# ENCODER0_REG_TOPAZ_VLC_CORE_0 register map
Vendor: Texas Instruments
Peripheral module from a debugger description file (folder J7ES).
Registers are 32-bit, read-only, reset values left out (the file's numbers can be read two ways) unless marked. A register's access mark holds for its fields unless they carry their own. Offsets are as the file gives them; lines under a group give offsets from that group; [hi:lo] are bit positions; {n}, {i} and the like mark numbered series; 'fields as' and 'values as' point back to an identical list; <NAME> marks a mode.

## ENCODER0_REG_TOPAZ_VLC_CORE_0
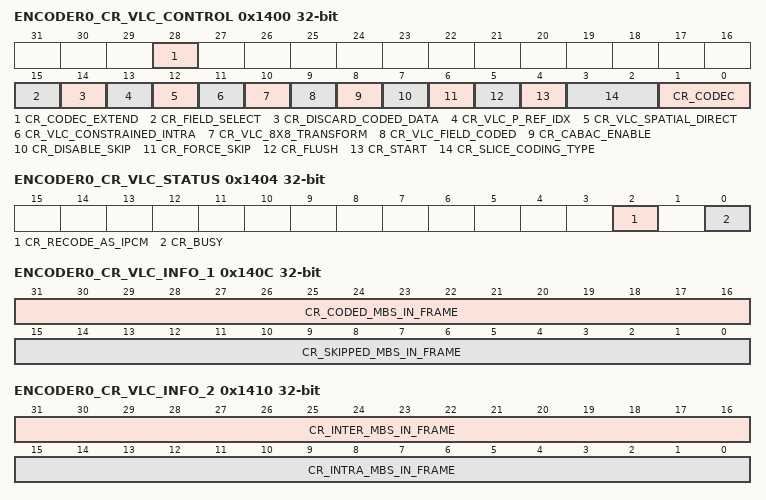
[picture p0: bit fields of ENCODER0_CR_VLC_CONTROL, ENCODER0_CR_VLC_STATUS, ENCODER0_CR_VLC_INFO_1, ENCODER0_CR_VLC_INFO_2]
0x1400 ENCODER0_CR_VLC_CONTROL access per field — The action of writing to this register with the START bit set to '1' causes VLC to begin processing. This is typically used to trigger header/stuffing insertion or a VLC flush.VLC can also be triggered directly by the H/W sequencer. This is typically used to trigger MB processing.
  [28] CR_CODEC_EXTEND rw — Extension to the CODEC field
  [15] CR_FIELD_SELECT rw — Selects the reference field
  [14] CR_DISCARD_CODED_DATA rw
  [13] CR_VLC_P_REF_IDX rw — 0 : Does not generate the ref_idx_l0 symbol on P slices
  [12] CR_VLC_SPATIAL_DIRECT rw — 0: Direct motion vectors are calculated as Tempoal Direct
  [11] CR_VLC_CONSTRAINED_INTRA rw — 0: Intra prediction can use boundary pixels from Inter MBs
  [10] CR_VLC_8X8_TRANSFORM rw — 0: Use 4x4 transform for Inter MB, disable Luma Intra 8x8 prediction
  [9] CR_VLC_FIELD_CODED rw — 0 : Encoding frame picture
  [8] CR_CABAC_ENABLE rw
  [7] CR_DISABLE_SKIP rw
  [6] CR_FORCE_SKIP rw
  [5] CR_FLUSH rw — 0 : A flush operation is NOT performed
  [4] CR_START rw — 0: The VLC module is NOT triggered.
  [3:2] CR_SLICE_CODING_TYPE rw — 0x0: I slice
  [1:0] CR_CODEC rw — if CR_CODEC_EXTEND = '0' if CR_CODEC_EXTEND = '1'
0x1404 ENCODER0_CR_VLC_STATUS
  [2] CR_RECODE_AS_IPCM, [0] CR_BUSY
0x1408 ENCODER0_CR_VLC_INFO_0
  [17:13] CR_FLUSH_STUFFING_BYTES — The number of stuffing bytes that were inserted into the bitstream during the last flush operation
0x140C ENCODER0_CR_VLC_INFO_1 rw
  [31:16] CR_CODED_MBS_IN_FRAME — The total number of coded MBs in the current inter frame.
  [15:0] CR_SKIPPED_MBS_IN_FRAME — Total number of skipped MBs in the current inter frame.
0x1410 ENCODER0_CR_VLC_INFO_2 rw
  [31:16] CR_INTER_MBS_IN_FRAME — The number of inter MBs in the current frame.
  [15:0] CR_INTRA_MBS_IN_FRAME — The total number of intra MBs in the current inter frame.
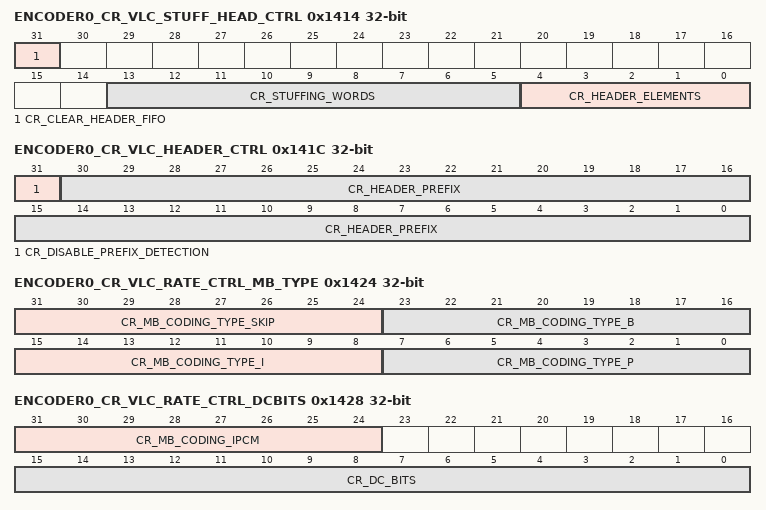
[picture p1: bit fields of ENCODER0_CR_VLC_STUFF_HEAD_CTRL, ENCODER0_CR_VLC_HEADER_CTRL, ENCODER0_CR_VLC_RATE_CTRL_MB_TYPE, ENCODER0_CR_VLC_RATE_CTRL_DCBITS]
0x1414 ENCODER0_CR_VLC_STUFF_HEAD_CTRL access per field
  [31] CR_CLEAR_HEADER_FIFO rw — 1: Causes the header fifo to be emptied
  [13:5] CR_STUFFING_WORDS rw — The number of stuffing bytes to be inserted DIV 4.
  [4:0] CR_HEADER_ELEMENTS rw — The number of header elements to be inserted.
0x1418 ENCODER0_CR_VLC_HEADER_FIFO rw
  [31:0] CR_HEADER_DATA — Header data to be inserted by VLC, written as encoded bitstream in a particular format.
0x141C ENCODER0_CR_VLC_HEADER_CTRL rw
  [31] CR_DISABLE_PREFIX_DETECTION — 0 : Prefix detection is enabled.
  [30:0] CR_HEADER_PREFIX — Each bit in this field indicates that the corresponding header element contains a start code prefix in the first 3 bytes.
0x1420 ENCODER0_CR_VLC_HEADER_STATUS
  [0] CR_HEADER_FIFO_FULL
0x1424 ENCODER0_CR_VLC_RATE_CTRL_MB_TYPE — All of the rate control registers are double buffered, and accumulated over a basic unit. The hardware contains internal registers which increment as macroblocks are processed. At the start of the next basic unit, the internal registers are copied into the rate control registers which can be read by software. This is used by the rate control.
  [31:24] CR_MB_CODING_TYPE_SKIP — Count of the number of macroblocks in basic unit with MB_type of Skip
  [23:16] CR_MB_CODING_TYPE_B — Count of the number of macroblocks in basic unit with MB_type of B
  [15:8] CR_MB_CODING_TYPE_I — Count of the number of macroblocks in basic unit with MB_type of I
  [7:0] CR_MB_CODING_TYPE_P — Count of the number of macroblocks in basic unit with MB_type of P
0x1428 ENCODER0_CR_VLC_RATE_CTRL_DCBITS
  [31:24] CR_MB_CODING_IPCM — Count of the number of macroblocks in basic unit which were coded as Intra PCM
  [15:0] CR_DC_BITS — Number of bits used to code all 6 DC coefficients in the current MB, accumulated for all macroblocks in a basic unit.
0x142C ENCODER0_CR_VLC_RATE_CTRL_MVBITS
  [23:0] CR_MV_BITS — Number of bits used to code all the MVs in the current MB, accumulated for all macroblocks in a basic unit.
0x1430 ENCODER0_CR_VLC_RATE_CTRL_MBSYM
  [23:0] CR_MB_SYMBOLS_BITS — The number of bits used to code all the MB level symbols in the current MB, accumulated for all macroblocks in a basic unit.
0x1434 ENCODER0_CR_VLC_RATE_CTRL_MBRES
  [23:0] CR_MB_RESIDUAL_BITS — The number of bits used to code all the residual coefficients in the current MB, accumulated for all macroblocks in a basic unit.
0x1438 ENCODER0_CR_VLC_SIGNATURE_0
  [31:0] CR_MB_SIGNATURE — LFSR Signature of the output from the MB level Index Generator
0x143C ENCODER0_CR_VLC_SIGNATURE_1
  [31:0] CR_BLK_SIGNATURE — LFSR Signature of the output from the Block level Index Generators
0x1440 ENCODER0_CR_VLC_SIGNATURE_2
  [31:0] CR_LOOKUP_SIGNATURE — LFSR Signature of the output of the Code Lookup and Golomb Coding sub-module.
0x1444 ENCODER0_CR_VLC_SIGNATURE_3
  [31:0] CR_BITSTREAM_SIGNATURE — LFSR Signature of the bitstream generated by the VLC module, at the output of the Output Buffer.
0x1448 ENCODER0_CR_VLC_SIGNATURE_4
  [31:0] CR_HEADER_SIGNATURE — LFSR Signature of the output of the Stuffing and Header Insertion sub-module.
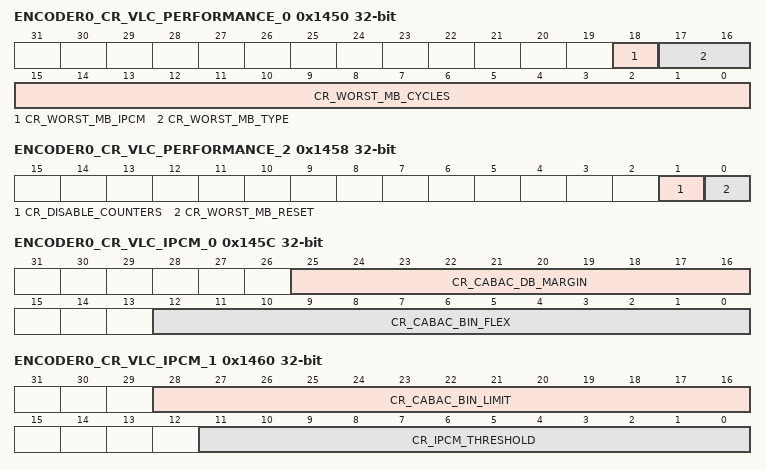
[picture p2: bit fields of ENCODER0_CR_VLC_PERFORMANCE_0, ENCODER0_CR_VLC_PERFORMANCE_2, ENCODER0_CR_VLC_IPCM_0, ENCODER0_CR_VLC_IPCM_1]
0x1450 ENCODER0_CR_VLC_PERFORMANCE_0 access per field
  [18] CR_WORST_MB_IPCM rw
  [17:16] CR_WORST_MB_TYPE rw — The MB type of the worst MB.
  [15:0] CR_WORST_MB_CYCLES rw — The number of cycles taken to process the worst MB.
0x1454 ENCODER0_CR_VLC_PERFORMANCE_1 access per field
  [21:0] CR_WORST_MB_NUM rw — The linear MB number of the worst MB.
0x1458 ENCODER0_CR_VLC_PERFORMANCE_2 access per field
  [1] CR_DISABLE_COUNTERS rw
  [0] CR_WORST_MB_RESET rw — Writing this single bit with the value '1' clears both performance registers and resets the worst MB Num counter
0x145C ENCODER0_CR_VLC_IPCM_0 access per field
  [25:16] CR_CABAC_DB_MARGIN rw — This field is only used in H264 CABAC mode when CR_CABAC_BIN_FLEX is not equal to 0, i.e.
  [12:0] CR_CABAC_BIN_FLEX rw — This field is only used in H264 CABAC mode, and indicates how much the bin limit is allowed to vary.
0x1460 ENCODER0_CR_VLC_IPCM_1 access per field
  [28:16] CR_CABAC_BIN_LIMIT rw — In H264 CABAC mode only, this field indicates the number of bins per macroblock which can be coded before the macroblock is recoded as I_PCM [Setting this field to zero will mean that the number of bins used is unlimited, so no macroblocks are recoded as I_PCM due to this bin limit.] This field in not used in other modes.
  [11:0] CR_IPCM_THRESHOLD rw — The threshold number of bits generated for a single H264 macroblock above which the macroblock should be recoded as I_PCM.
0x1464 ENCODER0_CR_VLC_MPEG4_CFG access per field
  [2:0] CR_RSIZE rw — This is the r_size parameter used in MPEG4 and H263 for encoding Motion Vectors.
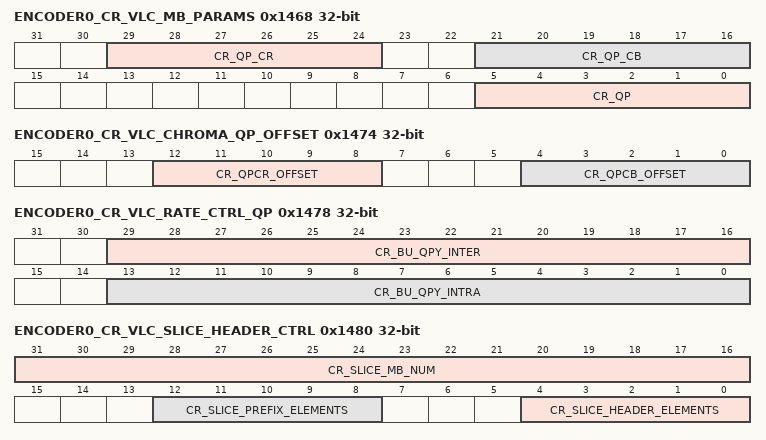
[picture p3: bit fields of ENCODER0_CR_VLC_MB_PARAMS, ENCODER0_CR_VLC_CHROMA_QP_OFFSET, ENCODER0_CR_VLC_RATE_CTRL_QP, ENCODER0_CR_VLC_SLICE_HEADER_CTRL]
0x1468 ENCODER0_CR_VLC_MB_PARAMS
  [29:24] CR_QP_CR — The QP value used for Cr data on the last MB of the previous BU.
  [21:16] CR_QP_CB — The QP value used for Cb data on the last MB of the previous BU.
  [5:0] CR_QP — QP in H264 [luma]
0x146C ENCODER0_CR_VLC_RESET access per field
  [0] CR_RESET rw
0x1470 ENCODER0_CR_VLC_WRITE_ADDR access per field
  [31:4] CR_NEXT_WRITE_ADDR rw — The next address that the VLC module will write stream data out to.
0x1474 ENCODER0_CR_VLC_CHROMA_QP_OFFSET access per field
  [12:8] CR_QPCR_OFFSET rw — Signed offset added to QPy [and then clipped to range 0 to 51] which is used to look-up QPCr from the QPC lookup table.
  [4:0] CR_QPCB_OFFSET rw — Signed offset added to QPy [and then clipped to range 0 to 51] which is used to look-up QPCb from the QPC lookup table.
0x1478 ENCODER0_CR_VLC_RATE_CTRL_QP — All of the rate control registers are double buffered, and accumulated over a basic unit. The hardware contains internal registers which increment as macroblocks are processed. At the start of the next basic unit, the internal registers are copied into the rate control registers which can be read by software. This is used by the rate control.
  [29:16] CR_BU_QPY_INTER — Sum of QPy/Qscale for all macroblocks in a basic unit which are inter [add 0 if macroblock is Intra]
  [13:0] CR_BU_QPY_INTRA — Sum of QPy/Qscale for all macroblocks in a basic unit which are intra [add 0 if macroblock is Inter]
0x147C ENCODER0_CR_VLC_BU_STAT_UPDATE access per field
  [0] CR_FORCE_BU_STAT_UPDATE rw — Normally the rate control registers in 0x024 to 0x034 plus 0x078 are updated at the start of the next basic unit.
0x1480 ENCODER0_CR_VLC_SLICE_HEADER_CTRL access per field
  [31:16] CR_SLICE_MB_NUM rw — At the start of a slice, should be set to the address of the first macroblock in that slice.
  [12:8] CR_SLICE_PREFIX_ELEMENTS rw — The count of elements in the slice header buffer, starting from the first element in the buffer, that should be output before the first_mb_in_slice symbol when generating a slice header
  [4:0] CR_SLICE_HEADER_ELEMENTS rw — The count of elements in the slice header buffer, starting after cr_slice_prefix_elements in the buffer, that should be output after the first_mb_in_slice symbol when generating a slice header.
0x1484 ENCODER0_CR_VLC_SLICE_CTRL_0 access per field
  [23:0] CR_SLICE_SIZE_LIMIT rw — Requested limit on the number of bytes in a slice
0x148C ENCODER0_CR_VLC_SLICE_CTRL_1 access per field
  [13:0] CR_SLICE_MBS_LIMIT rw — Requested limit on the number of macroblocks in a slice
0x1490 ENCODER0_CR_VLC_RATE_CTRL_HEADERS
  [23:0] CR_SLICE_HEADER_BITS — The number of bits used to code all the dynamic slice headers in the basic unit.
0x1494 ENCODER0_CR_VLC_SIGNATURE_5
  [31:0] CR_CABAC_SIGNATURE — LFSR Signature of the output from the CABAC Encoder
0x1498 ENCODER0_CR_VLC_SIGNATURE_6
  [31:0] CR_IPCM_SIGNATURE — LFSR Signature of the output from the I_PCM sub-module
